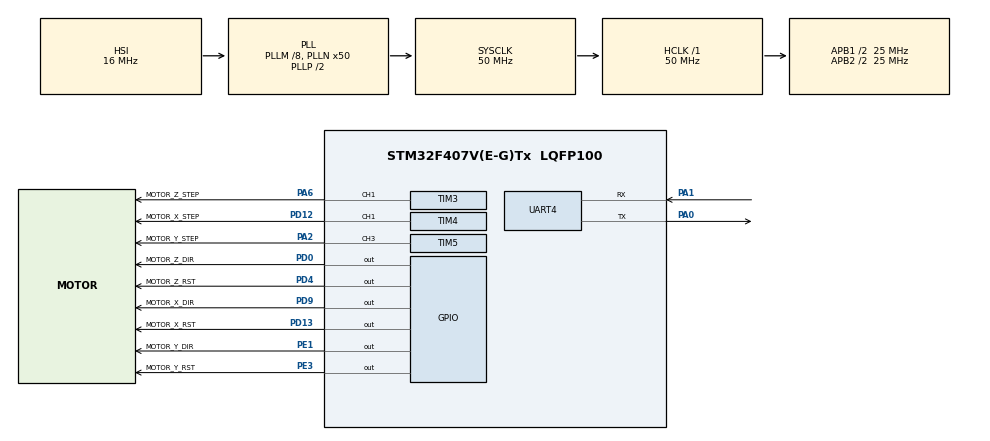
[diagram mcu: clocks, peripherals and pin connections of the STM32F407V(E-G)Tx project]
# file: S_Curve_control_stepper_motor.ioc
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Dma.Request0=UART4_RX
Dma.Request1=UART4_TX
Dma.UART4_RX.0.Direction=DMA_PERIPH_TO_MEMORY
Dma.UART4_RX.0.FIFOMode=DMA_FIFOMODE_DISABLE
Dma.UART4_RX.0.Instance=DMA1_Stream2
Dma.UART4_RX.0.MemDataAlignment=DMA_MDATAALIGN_BYTE
Dma.UART4_RX.0.MemInc=DMA_MINC_ENABLE
Dma.UART4_RX.0.Mode=DMA_NORMAL
Dma.UART4_RX.0.PeriphDataAlignment=DMA_PDATAALIGN_BYTE
Dma.UART4_RX.0.PeriphInc=DMA_PINC_DISABLE
Dma.UART4_RX.0.Priority=DMA_PRIORITY_LOW
Dma.UART4_TX.1.Direction=DMA_MEMORY_TO_PERIPH
Dma.UART4_TX.1.FIFOMode=DMA_FIFOMODE_DISABLE
Dma.UART4_TX.1.Instance=DMA1_Stream4
Dma.UART4_TX.1.MemDataAlignment=DMA_MDATAALIGN_BYTE
Dma.UART4_TX.1.MemInc=DMA_MINC_ENABLE
Dma.UART4_TX.1.Mode=DMA_NORMAL
Dma.UART4_TX.1.PeriphDataAlignment=DMA_PDATAALIGN_BYTE
Dma.UART4_TX.1.PeriphInc=DMA_PINC_DISABLE
Dma.UART4_TX.1.Priority=DMA_PRIORITY_LOW
Mcu.Family=STM32F4
Mcu.Name=STM32F407V(E-G)Tx
Mcu.Package=LQFP100
NVIC.DMA1_Stream2_IRQn=true\:0\:0\:false\:false\:true\:false\:true
NVIC.DMA1_Stream4_IRQn=true\:0\:0\:false\:false\:true\:false\:true
NVIC.PriorityGroup=NVIC_PRIORITYGROUP_4
NVIC.TIM2_IRQn=true\:0\:0\:false\:false\:true\:true\:true
NVIC.TIM3_IRQn=true\:0\:0\:false\:false\:true\:true\:true
NVIC.TIM4_IRQn=true\:0\:0\:false\:false\:true\:true\:true
NVIC.TIM5_IRQn=true\:0\:0\:false\:false\:true\:true\:true
NVIC.UART4_IRQn=true\:0\:0\:false\:false\:true\:true\:true
PA0-WKUP.Mode=Asynchronous
PA0-WKUP.Signal=UART4_TX
PA1.Mode=Asynchronous
PA1.Signal=UART4_RX
PA2.GPIO_Label=MOTOR_Y_STEP
PA2.Signal=S_TIM5_CH3
PA6.GPIO_Label=MOTOR_Z_STEP
PA6.Signal=S_TIM3_CH1
PD0.GPIO_Label=MOTOR_Z_DIR
PD0.Signal=GPIO_Output
PD12.GPIO_Label=MOTOR_X_STEP
PD12.Signal=S_TIM4_CH1
PD13.GPIO_Label=MOTOR_X_RST
PD13.Signal=GPIO_Output
PD4.GPIO_Label=MOTOR_Z_RST
PD4.GPIO_PuPd=GPIO_NOPULL
PD4.Signal=GPIO_Output
PD9.GPIO_Label=MOTOR_X_DIR
PD9.Signal=GPIO_Output
PE1.GPIO_Label=MOTOR_Y_DIR
PE1.Signal=GPIO_Output
PE3.GPIO_Label=MOTOR_Y_RST
PE3.Signal=GPIO_Output
ProjectManager.HeapSize=0x200
ProjectManager.StackSize=0x400
ProjectManager.TargetToolchain=STM32CubeIDE
RCC.48MHZClocksFreq_Value=25000000
RCC.AHBFreq_Value=50000000
RCC.APB1CLKDivider=RCC_HCLK_DIV2
RCC.APB1Freq_Value=25000000
RCC.APB1TimFreq_Value=50000000
RCC.APB2CLKDivider=RCC_HCLK_DIV2
RCC.APB2Freq_Value=25000000
RCC.APB2TimFreq_Value=50000000
RCC.CortexFreq_Value=50000000
RCC.HCLKFreq_Value=50000000
RCC.HSE_VALUE=25000000
RCC.HSI_VALUE=16000000
RCC.LSE_VALUE=32768
RCC.PLLM=8
RCC.PLLN=50
RCC.SYSCLKFreq_VALUE=50000000
RCC.SYSCLKSource=RCC_SYSCLKSOURCE_PLLCLK
RCC.VCOOutputFreq_Value=100000000
SH.S_TIM3_CH1.0=TIM3_CH1,PWM Generation1 CH1
SH.S_TIM4_CH1.0=TIM4_CH1,PWM Generation1 CH1
SH.S_TIM5_CH3.0=TIM5_CH3,PWM Generation3 CH3
TIM2.Period=1000-1
TIM2.Prescaler=500-1
TIM3.Channel-PWM\ Generation1\ CH1=TIM_CHANNEL_1
TIM3.Prescaler=50-1
TIM4.Channel-PWM\ Generation1\ CH1=TIM_CHANNEL_1
TIM4.Prescaler=5-1
TIM5.Channel-PWM\ Generation3\ CH3=TIM_CHANNEL_3
TIM5.Prescaler=5-1
UART4.VirtualMode=Asynchronous
VP_TIM2_VS_ClockSourceINT.Mode=Internal
VP_TIM3_VS_ClockSourceINT.Mode=Internal
VP_TIM4_VS_ClockSourceINT.Mode=Internal
VP_TIM5_VS_ClockSourceINT.Mode=Internal
board=custom

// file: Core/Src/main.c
/* USER CODE BEGIN Header */
/**
  ******************************************************************************
  * @file           : main.c
  * @brief          : Main program body
  ******************************************************************************
  * @attention
  *
  * <h2><center>&copy; Copyright (c) 2022 STMicroelectronics.
  * All rights reserved.</center></h2>
  *
  * This software component is licensed by ST under BSD 3-Clause license,
  * the "License"; You may not use this file except in compliance with the
  * License. You may obtain a copy of the License at:
  *                        opensource.org/licenses/BSD-3-Clause
  *
  ******************************************************************************
  */
/* USER CODE END Header */
#include "main.h"
#include "dma.h"
#include "tim.h"
#include "usart.h"
#include "gpio.h"

/* USER CODE BEGIN Includes */
//#include "Stepper_Control.h"
/* USER CODE END Includes */

void SystemClock_Config(void);

int main(void)
{

  /* MCU Configuration--------------------------------------------------------*/

  /* Reset of all peripherals, Initializes the Flash interface and the Systick. */
  HAL_Init();

  /* Configure the system clock */
  SystemClock_Config();

  /* Initialize all configured peripherals */
  MX_GPIO_Init();
  MX_TIM3_Init();
  MX_TIM4_Init();
  MX_TIM5_Init();
  MX_DMA_Init();
  MX_UART4_Init();
  MX_TIM2_Init();
  /* USER CODE BEGIN 2 */
  stepper_motor_init(0);
  stepper_motor_set_param(0, 400);
  /* USER CODE END 2 */
  HAL_TIM_Base_Start_IT(&htim2);
  /* Infinite loop */
  while (1)
  {

  }
}

void SystemClock_Config(void)
{
  RCC_OscInitTypeDef RCC_OscInitStruct = {0};
  RCC_ClkInitTypeDef RCC_ClkInitStruct = {0};

  /** Configure the main internal regulator output voltage
  */
  __HAL_RCC_PWR_CLK_ENABLE();
  __HAL_PWR_VOLTAGESCALING_CONFIG(PWR_REGULATOR_VOLTAGE_SCALE1);
  /** Initializes the RCC Oscillators according to the specified parameters
  * in the RCC_OscInitTypeDef structure.
  */
  RCC_OscInitStruct.OscillatorType = RCC_OSCILLATORTYPE_HSI;
  RCC_OscInitStruct.HSIState = RCC_HSI_ON;
  RCC_OscInitStruct.HSICalibrationValue = RCC_HSICALIBRATION_DEFAULT;
  RCC_OscInitStruct.PLL.PLLState = RCC_PLL_ON;
  RCC_OscInitStruct.PLL.PLLSource = RCC_PLLSOURCE_HSI;
  RCC_OscInitStruct.PLL.PLLM = 8;
  RCC_OscInitStruct.PLL.PLLN = 50;
  RCC_OscInitStruct.PLL.PLLP = RCC_PLLP_DIV2;
  RCC_OscInitStruct.PLL.PLLQ = 4;
  if (HAL_RCC_OscConfig(&RCC_OscInitStruct) != HAL_OK)
  {
    Error_Handler();
  }
  /** Initializes the CPU, AHB and APB buses clocks
  */
  RCC_ClkInitStruct.ClockType = RCC_CLOCKTYPE_HCLK|RCC_CLOCKTYPE_SYSCLK
                              |RCC_CLOCKTYPE_PCLK1|RCC_CLOCKTYPE_PCLK2;
  RCC_ClkInitStruct.SYSCLKSource = RCC_SYSCLKSOURCE_PLLCLK;
  RCC_ClkInitStruct.AHBCLKDivider = RCC_SYSCLK_DIV1;
  RCC_ClkInitStruct.APB1CLKDivider = RCC_HCLK_DIV2;
  RCC_ClkInitStruct.APB2CLKDivider = RCC_HCLK_DIV2;

  if (HAL_RCC_ClockConfig(&RCC_ClkInitStruct, FLASH_LATENCY_1) != HAL_OK)
  {
    Error_Handler();
  }
}

void Error_Handler(void)
{
  __disable_irq();
  while (1)
  {
  }
}

/************************ (C) COPYRIGHT STMicroelectronics *****END OF FILE****/
